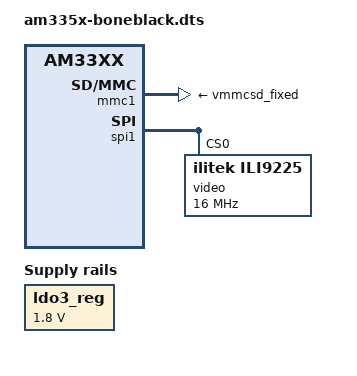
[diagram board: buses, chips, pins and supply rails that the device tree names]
/*
 * Copyright (C) 2012 Texas Instruments Incorporated - http://www.ti.com/
 *
 * This program is free software; you can redistribute it and/or modify
 * it under the terms of the GNU General Public License version 2 as
 * published by the Free Software Foundation.
 */
/dts-v1/;

#include "am33xx.dtsi"
#include "am335x-bone-common.dtsi"

&ldo3_reg {
	regulator-min-microvolt = <1800000>;
	regulator-max-microvolt = <1800000>;
	regulator-always-on;
};

&mmc1 {
	vmmc-supply = <&vmmcsd_fixed>;
};


&am33xx_pinmux {
	spi1_pins: spi1_pins {
	pinctrl-single,pins = <
			0xD0	 (PIN_OUTPUT_PULLUP   | MUX_MODE7)
			0xD4	 (PIN_OUTPUT_PULLUP   | MUX_MODE7)
		       	0x190    (PIN_OUTPUT_PULLUP   | MUX_MODE3)
		      	/*0x194     (PIN_INPUT_PULLUP | MUX_MODE3)*/
		       	0x198     (PIN_OUTPUT_PULLUP  | MUX_MODE3)
		       	0x19C     (PIN_OUTPUT_PULLUP  | MUX_MODE3)
		        >;
	};

};



&spi1 {
	status	= "okay";
	pinctrl-names = "default";
	pinctrl-0 = <&spi1_pins>;
	video: video@0 {
		compatible = "ilitek,ili9225";
		spi-max-frequency = <16000000>;
		reg = <0>;
		spi-cpol;
		spi-cpha;
	};
};




